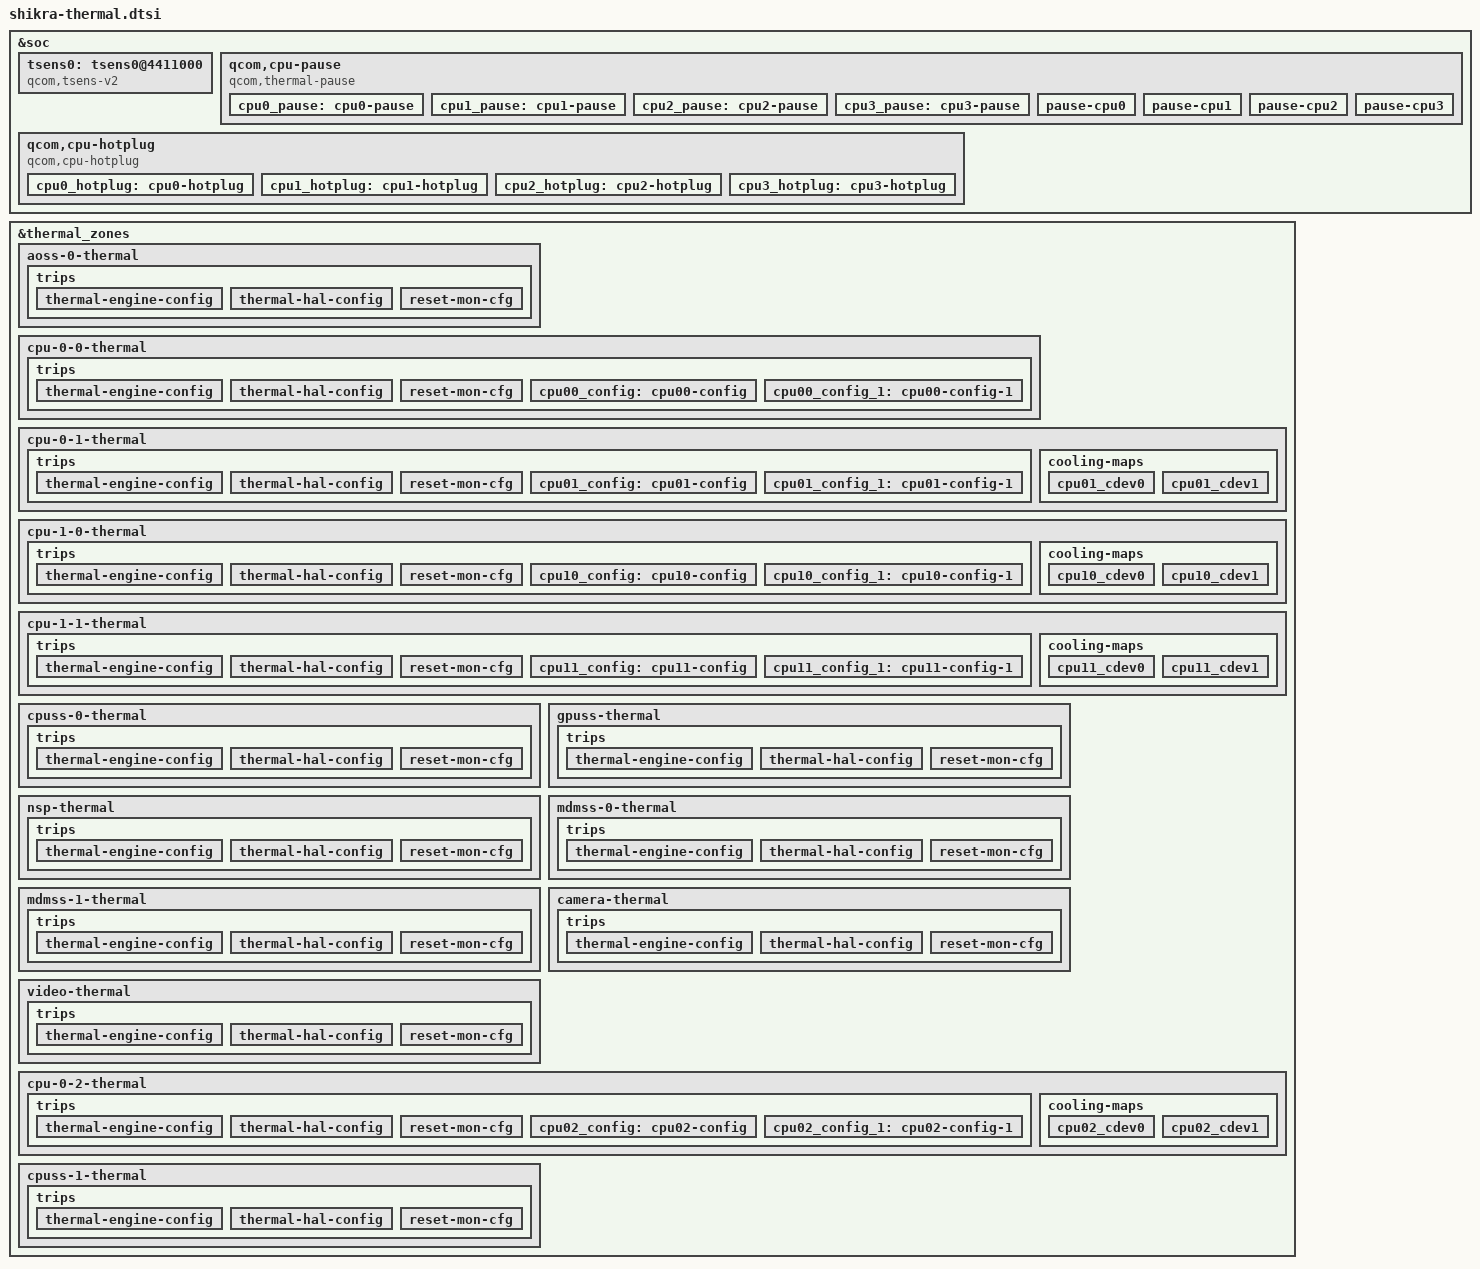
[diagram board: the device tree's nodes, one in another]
// SPDX-License-Identifier: BSD-3-Clause
/*
 * Copyright (c) Qualcomm Technologies, Inc. and/or its subsidiaries.
 */

#include <dt-bindings/thermal/thermal_qti.h>

&soc {
	tsens0: tsens0@4411000 {
		compatible = "qcom,tsens-v2";
		reg = <0x04411000 0x1ff>, /* TM */
				<0x04410000 0x1ff>; /* SROT */
		#qcom,sensors = <14>;
		interrupts = <GIC_SPI 275 IRQ_TYPE_LEVEL_HIGH>,
				<GIC_SPI 190 IRQ_TYPE_LEVEL_HIGH>;
		interrupt-names = "uplow","critical";
		#thermal-sensor-cells = <1>;
	};

	qcom,cpu-pause {
		compatible = "qcom,thermal-pause";
		cpu0_pause: cpu0-pause {
			qcom,cpus = <&CPU0>;
			qcom,cdev-alias = "thermal-pause-1";
			#cooling-cells = <2>;
		};

		cpu1_pause: cpu1-pause {
			qcom,cpus = <&CPU1>;
			qcom,cdev-alias = "thermal-pause-2";
			#cooling-cells = <2>;
		};

		cpu2_pause: cpu2-pause {
			qcom,cpus = <&CPU2>;
			qcom,cdev-alias = "thermal-pause-4";
			#cooling-cells = <2>;
		};

		cpu3_pause: cpu3-pause {
			qcom,cpus = <&CPU3>;
			qcom,cdev-alias = "thermal-pause-8";
			#cooling-cells = <2>;
		};

		/* Thermal-engine cooling devices */
		pause-cpu0 {
			qcom,cpus = <&CPU0>;
			qcom,cdev-alias = "pause-cpu0";
		};

		pause-cpu1 {
			qcom,cpus = <&CPU1>;
			qcom,cdev-alias = "pause-cpu1";
		};

		pause-cpu2 {
			qcom,cpus = <&CPU2>;
			qcom,cdev-alias = "pause-cpu2";
		};

		pause-cpu3 {
			qcom,cpus = <&CPU3>;
			qcom,cdev-alias = "pause-cpu3";
		};
	};

	qcom,cpu-hotplug {
		compatible = "qcom,cpu-hotplug";
		cpu0_hotplug: cpu0-hotplug {
			qcom,cpu = <&CPU0>;
			qcom,cdev-alias = "cpu-hotplug0";
			#cooling-cells = <2>;
		};

		cpu1_hotplug: cpu1-hotplug {
			qcom,cpu = <&CPU1>;
			qcom,cdev-alias = "cpu-hotplug1";
			#cooling-cells = <2>;
		};

		cpu2_hotplug: cpu2-hotplug {
			qcom,cpu = <&CPU2>;
			qcom,cdev-alias = "cpu-hotplug2";
			#cooling-cells = <2>;
		};

		cpu3_hotplug: cpu3-hotplug {
			qcom,cpu = <&CPU3>;
			qcom,cdev-alias = "cpu-hotplug3";
			#cooling-cells = <2>;
		};
	};
};

&thermal_zones {
	aoss-0-thermal {
		polling-delay-passive = <0>;
		polling-delay = <0>;
		thermal-sensors = <&tsens0 0>;
		trips {
			thermal-engine-config {
				temperature = <125000>;
				hysteresis = <5000>;
				type = "passive";
			};

			thermal-hal-config {
				temperature = <95000>;
				hysteresis = <5000>;
				type = "passive";
			};

			reset-mon-cfg {
				temperature = <115000>;
				hysteresis = <5000>;
				type = "hot";
			};
		};
	};

	cpu-0-0-thermal {
		polling-delay-passive = <0>;
		polling-delay = <0>;
		thermal-sensors = <&tsens0 1>;
		trips {
			thermal-engine-config {
				temperature = <125000>;
				hysteresis = <5000>;
				type = "passive";
			};

			thermal-hal-config {
				temperature = <95000>;
				hysteresis = <5000>;
				type = "passive";
			};

			reset-mon-cfg {
				temperature = <115000>;
				hysteresis = <5000>;
				type = "hot";
			};

			cpu00_config: cpu00-config {
				temperature = <110000>;
				hysteresis = <10000>;
				type = "passive";
			};

			cpu00_config_1: cpu00-config-1 {
				temperature = <112000>;
				hysteresis = <10000>;
				type = "passive";
			};
		};
	};

	cpu-0-1-thermal {
		polling-delay-passive = <0>;
		polling-delay = <0>;
		thermal-sensors = <&tsens0 2>;
		trips {
			thermal-engine-config {
				temperature = <125000>;
				hysteresis = <5000>;
				type = "passive";
			};

			thermal-hal-config {
				temperature = <95000>;
				hysteresis = <5000>;
				type = "passive";
			};

			reset-mon-cfg {
				temperature = <115000>;
				hysteresis = <5000>;
				type = "hot";
			};

			cpu01_config: cpu01-config {
				temperature = <110000>;
				hysteresis = <10000>;
				type = "passive";
			};

			cpu01_config_1: cpu01-config-1 {
				temperature = <112000>;
				hysteresis = <10000>;
				type = "passive";
			};
		};

		cooling-maps {
			cpu01_cdev0 {
				trip = <&cpu01_config>;
				cooling-device = <&cpu1_pause 0 1>;
			};

			cpu01_cdev1 {
				trip = <&cpu01_config_1>;
				cooling-device = <&cpu1_hotplug 0 1>;
			};
		};
	};

	cpu-1-0-thermal {
		polling-delay-passive = <0>;
		polling-delay = <0>;
		thermal-sensors = <&tsens0 3>;
		trips {
			thermal-engine-config {
				temperature = <125000>;
				hysteresis = <5000>;
				type = "passive";
			};

			thermal-hal-config {
				temperature = <95000>;
				hysteresis = <5000>;
				type = "passive";
			};

			reset-mon-cfg {
				temperature = <115000>;
				hysteresis = <5000>;
				type = "hot";
			};

			cpu10_config: cpu10-config {
				temperature = <110000>;
				hysteresis = <10000>;
				type = "passive";
			};

			cpu10_config_1: cpu10-config-1 {
				temperature = <112000>;
				hysteresis = <10000>;
				type = "passive";
			};
		};

		cooling-maps {
			cpu10_cdev0 {
				trip = <&cpu10_config>;
				cooling-device = <&cpu3_pause 0 1>;
			};

			cpu10_cdev1 {
				trip = <&cpu10_config_1>;
				cooling-device = <&cpu3_hotplug 0 1>;
			};
		};
	};

	cpu-1-1-thermal {
		polling-delay-passive = <0>;
		polling-delay = <0>;
		thermal-sensors = <&tsens0 4>;
		trips {
			thermal-engine-config {
				temperature = <125000>;
				hysteresis = <5000>;
				type = "passive";
			};

			thermal-hal-config {
				temperature = <95000>;
				hysteresis = <5000>;
				type = "passive";
			};

			reset-mon-cfg {
				temperature = <115000>;
				hysteresis = <5000>;
				type = "hot";
			};

			cpu11_config: cpu11-config {
				temperature = <110000>;
				hysteresis = <10000>;
				type = "passive";
			};

			cpu11_config_1: cpu11-config-1 {
				temperature = <112000>;
				hysteresis = <10000>;
				type = "passive";
			};
		};

		cooling-maps {
			cpu11_cdev0 {
				trip = <&cpu11_config>;
				cooling-device = <&cpu3_pause 0 1>;
			};

			cpu11_cdev1 {
				trip = <&cpu11_config_1>;
				cooling-device = <&cpu3_hotplug 0 1>;
			};
		};
	};

	cpuss-0-thermal {
		polling-delay-passive = <0>;
		polling-delay = <0>;
		thermal-sensors = <&tsens0 5>;
		trips {
			thermal-engine-config {
				temperature = <125000>;
				hysteresis = <5000>;
				type = "passive";
			};

			thermal-hal-config {
				temperature = <95000>;
				hysteresis = <5000>;
				type = "passive";
			};

			reset-mon-cfg {
				temperature = <115000>;
				hysteresis = <5000>;
				type = "hot";
			};
		};
	};

	gpuss-thermal {
		polling-delay-passive = <12>;
		polling-delay = <0>;
		thermal-sensors = <&tsens0 6>;
		trips {
			thermal-engine-config {
				temperature = <125000>;
				hysteresis = <5000>;
				type = "passive";
			};

			thermal-hal-config {
				temperature = <95000>;
				hysteresis = <5000>;
				type = "passive";
			};

			reset-mon-cfg {
				temperature = <115000>;
				hysteresis = <5000>;
				type = "hot";
			};
		};
	};

	nsp-thermal {
		polling-delay-passive = <0>;
		polling-delay = <0>;
		thermal-sensors = <&tsens0 7>;
		trips {
			thermal-engine-config {
				temperature = <125000>;
				hysteresis = <5000>;
				type = "passive";
			};

			thermal-hal-config {
				temperature = <95000>;
				hysteresis = <5000>;
				type = "passive";
			};

			reset-mon-cfg {
				temperature = <115000>;
				hysteresis = <5000>;
				type = "hot";
			};
		};
	};

	mdmss-0-thermal {
		polling-delay-passive = <0>;
		polling-delay = <0>;
		thermal-sensors = <&tsens0 8>;
		trips {
			thermal-engine-config {
				temperature = <125000>;
				hysteresis = <5000>;
				type = "passive";
			};

			thermal-hal-config {
				temperature = <95000>;
				hysteresis = <5000>;
				type = "passive";
			};

			reset-mon-cfg {
				temperature = <115000>;
				hysteresis = <5000>;
				type = "hot";
			};
		};
	};

	mdmss-1-thermal {
		polling-delay-passive = <0>;
		polling-delay = <0>;
		thermal-sensors = <&tsens0 9>;
		trips {
			thermal-engine-config {
				temperature = <125000>;
				hysteresis = <5000>;
				type = "passive";
			};

			thermal-hal-config {
				temperature = <95000>;
				hysteresis = <5000>;
				type = "passive";
			};

			reset-mon-cfg {
				temperature = <115000>;
				hysteresis = <5000>;
				type = "hot";
			};
		};
	};

	camera-thermal {
		polling-delay-passive = <0>;
		polling-delay = <0>;
		thermal-sensors = <&tsens0 10>;
		trips {
			thermal-engine-config {
				temperature = <125000>;
				hysteresis = <5000>;
				type = "passive";
			};

			thermal-hal-config {
				temperature = <95000>;
				hysteresis = <5000>;
				type = "passive";
			};

			reset-mon-cfg {
				temperature = <115000>;
				hysteresis = <5000>;
				type = "hot";
			};
		};
	};

	video-thermal {
		polling-delay-passive = <0>;
		polling-delay = <0>;
		thermal-sensors = <&tsens0 11>;
		trips {
			thermal-engine-config {
				temperature = <125000>;
				hysteresis = <5000>;
				type = "passive";
			};

			thermal-hal-config {
				temperature = <95000>;
				hysteresis = <5000>;
				type = "passive";
			};

			reset-mon-cfg {
				temperature = <115000>;
				hysteresis = <5000>;
				type = "hot";
			};
		};
	};

	cpu-0-2-thermal {
		polling-delay-passive = <0>;
		polling-delay = <0>;
		thermal-sensors = <&tsens0 12>;
		trips {
			thermal-engine-config {
				temperature = <125000>;
				hysteresis = <5000>;
				type = "passive";
			};

			thermal-hal-config {
				temperature = <95000>;
				hysteresis = <5000>;
				type = "passive";
			};

			reset-mon-cfg {
				temperature = <115000>;
				hysteresis = <5000>;
				type = "hot";
			};

			cpu02_config: cpu02-config {
				temperature = <110000>;
				hysteresis = <10000>;
				type = "passive";
			};

			cpu02_config_1: cpu02-config-1 {
				temperature = <112000>;
				hysteresis = <10000>;
				type = "passive";
			};
		};

		cooling-maps {
			cpu02_cdev0 {
				trip = <&cpu02_config>;
				cooling-device = <&cpu2_pause 0 1>;
			};

			cpu02_cdev1 {
				trip = <&cpu02_config_1>;
				cooling-device = <&cpu2_hotplug 0 1>;
			};
		};
	};

	cpuss-1-thermal {
		polling-delay-passive = <0>;
		polling-delay = <0>;
		thermal-sensors = <&tsens0 13>;
		trips {
			thermal-engine-config {
				temperature = <125000>;
				hysteresis = <5000>;
				type = "passive";
			};

			thermal-hal-config {
				temperature = <95000>;
				hysteresis = <5000>;
				type = "passive";
			};

			reset-mon-cfg {
				temperature = <115000>;
				hysteresis = <5000>;
				type = "hot";
			};
		};
	};
};
